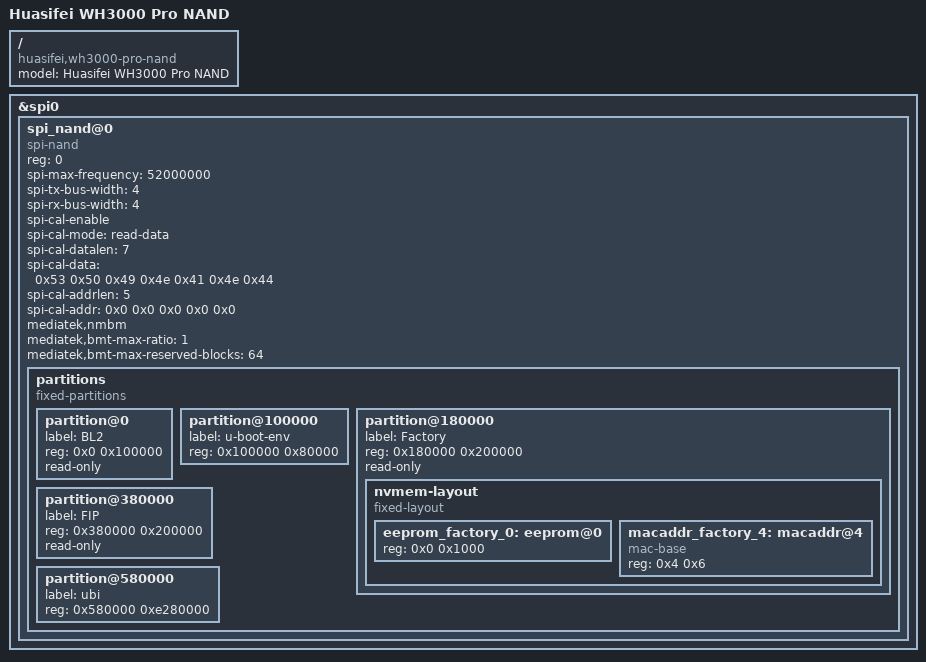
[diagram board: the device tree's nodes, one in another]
// SPDX-License-Identifier: GPL-2.0-or-later OR MIT

/dts-v1/;

#include "mt7981b-huasifei-wh3000-pro.dtsi"

/ {
	model = "Huasifei WH3000 Pro NAND";
	compatible = "huasifei,wh3000-pro-nand", "mediatek,mt7981";
};

&spi0 {
	status = "okay";

	spi_nand@0 {
		compatible = "spi-nand";
		reg = <0>;

		spi-max-frequency = <52000000>;
		spi-tx-bus-width = <4>;
		spi-rx-bus-width = <4>;

		spi-cal-enable;
		spi-cal-mode = "read-data";
		spi-cal-datalen = <7>;
		spi-cal-data = /bits/ 8 <0x53 0x50 0x49 0x4e 0x41 0x4e 0x44>;
		spi-cal-addrlen = <5>;
		spi-cal-addr = /bits/ 32 <0x0 0x0 0x0 0x0 0x0>;

		mediatek,nmbm;
		mediatek,bmt-max-ratio = <1>;
		mediatek,bmt-max-reserved-blocks = <64>;

		partitions {
			compatible = "fixed-partitions";
			#address-cells = <1>;
			#size-cells = <1>;

			partition@0 {
				label = "BL2";
				reg = <0x0 0x100000>;
				read-only;
			};

			partition@100000 {
				label = "u-boot-env";
				reg = <0x100000 0x80000>;
			};

			partition@180000 {
				label = "Factory";
				reg = <0x180000 0x200000>;
				read-only;

				nvmem-layout {
					compatible = "fixed-layout";
					#address-cells = <1>;
					#size-cells = <1>;

					eeprom_factory_0: eeprom@0 {
						reg = <0x0 0x1000>;
					};

					macaddr_factory_4: macaddr@4 {
						compatible = "mac-base";
						reg = <0x4 0x6>;
						#nvmem-cell-cells = <1>;
					};
				};
			};

			partition@380000 {
				label = "FIP";
				reg = <0x380000 0x200000>;
				read-only;
			};

			partition@580000 {
				label = "ubi";
				reg = <0x580000 0xe280000>;
			};
		};
	};
};
